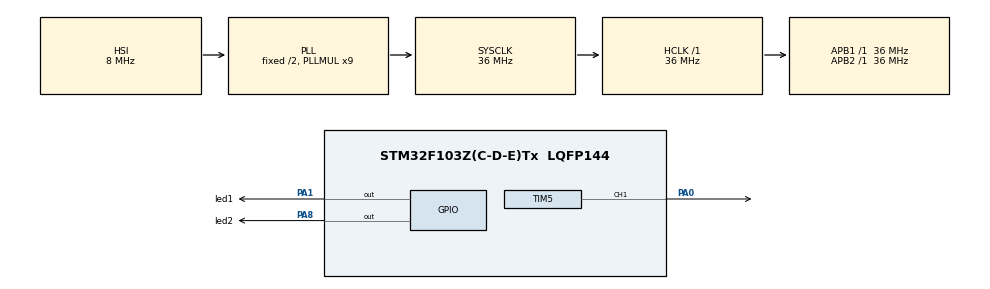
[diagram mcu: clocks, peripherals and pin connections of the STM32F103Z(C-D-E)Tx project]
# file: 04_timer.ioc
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Mcu.Family=STM32F1
Mcu.Name=STM32F103Z(C-D-E)Tx
Mcu.Package=LQFP144
NVIC.PriorityGroup=NVIC_PRIORITYGROUP_4
NVIC.TIM6_IRQn=true\:0\:0\:false\:false\:true\:true\:true\:true
OSC_IN.Mode=HSE-External-Oscillator
OSC_IN.Signal=RCC_OSC_IN
OSC_OUT.Mode=HSE-External-Oscillator
OSC_OUT.Signal=RCC_OSC_OUT
PA0-WKUP.Signal=S_TIM5_CH1
PA1.GPIO_Label=led1
PA1.GPIO_PuPd=GPIO_PULLDOWN
PA1.PinState=GPIO_PIN_SET
PA1.Signal=GPIO_Output
PA13.Mode=Trace_Synchro_1bit_JTAG
PA13.Signal=SYS_JTMS-SWDIO
PA14.Mode=Trace_Synchro_1bit_JTAG
PA14.Signal=SYS_JTCK-SWCLK
PA15.Mode=Trace_Synchro_1bit_JTAG
PA15.Signal=SYS_JTDI
PA8.GPIO_Label=led2
PA8.Signal=GPIO_Output
PB3.Mode=Trace_Synchro_1bit_JTAG
PB3.Signal=SYS_JTDO-TRACESWO
PC14-OSC32_IN.Mode=LSE-External-Oscillator
PC14-OSC32_IN.Signal=RCC_OSC32_IN
PC15-OSC32_OUT.Mode=LSE-External-Oscillator
PC15-OSC32_OUT.Signal=RCC_OSC32_OUT
PE2.Mode=Trace_Synchro_1bit_JTAG
PE2.Signal=SYS_TRACECLK
PE3.Mode=Trace_Synchro_1bit_JTAG
PE3.Signal=SYS_TRACED0
ProjectManager.HeapSize=0x200
ProjectManager.StackSize=0x400
ProjectManager.TargetToolchain=CMake
RCC.AHBFreq_Value=36000000
RCC.APB1Freq_Value=36000000
RCC.APB1TimFreq_Value=36000000
RCC.APB2Freq_Value=36000000
RCC.APB2TimFreq_Value=36000000
RCC.HCLKFreq_Value=36000000
RCC.PLLMUL=RCC_PLL_MUL9
RCC.SYSCLKFreq_VALUE=36000000
RCC.SYSCLKSource=RCC_SYSCLKSOURCE_PLLCLK
RCC.USBFreq_Value=36000000
SH.S_TIM5_CH1.0=TIM5_CH1,PWM Generation1 CH1
TIM5.AutoReloadPreload=TIM_AUTORELOAD_PRELOAD_DISABLE
TIM5.Channel-PWM\ Generation1\ CH1=TIM_CHANNEL_1
TIM5.Period=99
TIM5.Prescaler=7199
TIM6.Period=9999
TIM6.Prescaler=4
VP_TIM5_VS_ClockSourceINT.Mode=Internal
VP_TIM6_VS_ClockSourceINT.Mode=Enable_Timer
board=custom

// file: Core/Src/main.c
/* USER CODE BEGIN Header */
/**
  ******************************************************************************
  * @file           : main.c
  * @brief          : Main program body
  ******************************************************************************
  * @attention
  *
  * Copyright (c) 2026 STMicroelectronics.
  * All rights reserved.
  *
  * This software is licensed under terms that can be found in the LICENSE file
  * in the root directory of this software component.
  * If no LICENSE file comes with this software, it is provided AS-IS.
  *
  ******************************************************************************
  */
/* USER CODE END Header */
#include "main.h"

#include <stdio.h>

#include "tim.h"
#include "gpio.h"

void SystemClock_Config(void);

int main(void)
{

    /* MCU Configuration--------------------------------------------------------*/

    /* Reset of all peripherals, Initializes the Flash interface and the Systick. */
    HAL_Init();

    /* Configure the system clock */
    SystemClock_Config();

    /* Initialize all configured peripherals */
    MX_GPIO_Init();
    MX_TIM6_Init();
    MX_TIM5_Init();

    /* USER CODE BEGIN 2 */

    // 开启基础定时器
    HAL_TIM_Base_Start(&htim6);

    // 开启PWM输出 tim5，TIM5_CH1 对应 PA0
    HAL_TIM_PWM_Start(&htim5, TIM_CHANNEL_1);

    int duty_cycle = 0;    // 用 int，直观
    const int step = 3;    // 步长固定为 1
    int direction = 1;     // 方向：+1 渐亮 / -1 渐暗

    /* USER CODE END 2 */

    /* Infinite loop */
    while (1)
    {

        // 边界翻转
        if (duty_cycle <= 0)   direction = 1;
        if (duty_cycle >= 100) direction = -1;

        duty_cycle += direction * step;

        TIM5_SetDutyCycle((uint8_t)duty_cycle);

        HAL_Delay(20);

    }
}

void SystemClock_Config(void)
{
    RCC_OscInitTypeDef RCC_OscInitStruct = {0};
    RCC_ClkInitTypeDef RCC_ClkInitStruct = {0};

    /** Initializes the RCC Oscillators according to the specified parameters
    * in the RCC_OscInitTypeDef structure.
    */
    RCC_OscInitStruct.OscillatorType = RCC_OSCILLATORTYPE_HSI;
    RCC_OscInitStruct.HSIState = RCC_HSI_ON;
    RCC_OscInitStruct.HSICalibrationValue = RCC_HSICALIBRATION_DEFAULT;
    RCC_OscInitStruct.PLL.PLLState = RCC_PLL_ON;
    RCC_OscInitStruct.PLL.PLLSource = RCC_PLLSOURCE_HSI_DIV2;
    RCC_OscInitStruct.PLL.PLLMUL = RCC_PLL_MUL9;
    if (HAL_RCC_OscConfig(&RCC_OscInitStruct) != HAL_OK)
    {
        Error_Handler();
    }

    /** Initializes the CPU, AHB and APB buses clocks
    */
    RCC_ClkInitStruct.ClockType = RCC_CLOCKTYPE_HCLK | RCC_CLOCKTYPE_SYSCLK
        | RCC_CLOCKTYPE_PCLK1 | RCC_CLOCKTYPE_PCLK2;
    RCC_ClkInitStruct.SYSCLKSource = RCC_SYSCLKSOURCE_PLLCLK;
    RCC_ClkInitStruct.AHBCLKDivider = RCC_SYSCLK_DIV1;
    RCC_ClkInitStruct.APB1CLKDivider = RCC_HCLK_DIV1;
    RCC_ClkInitStruct.APB2CLKDivider = RCC_HCLK_DIV1;

    if (HAL_RCC_ClockConfig(&RCC_ClkInitStruct, FLASH_LATENCY_1) != HAL_OK)
    {
        Error_Handler();
    }
}

void Error_Handler(void)
{
    __disable_irq();
    while (1)
    {
    }
}
